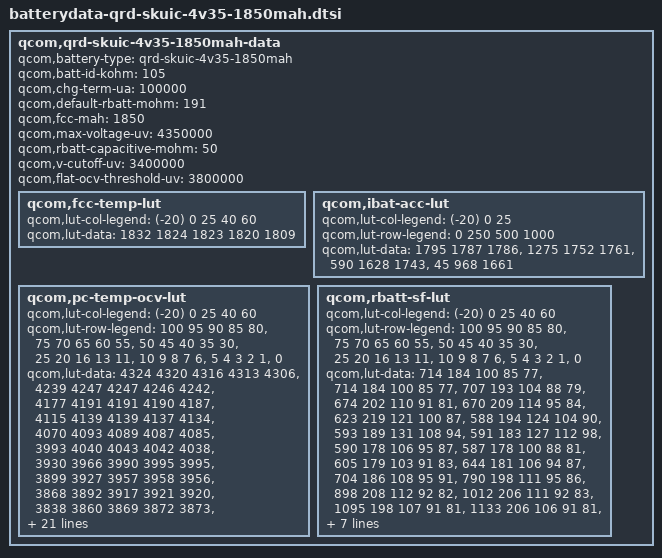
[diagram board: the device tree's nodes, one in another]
/* Copyright (c) 2014, The Linux Foundation. All rights reserved.
 *
 * This program is free software; you can redistribute it and/or modify
 * it under the terms of the GNU General Public License version 2 and
 * only version 2 as published by the Free Software Foundation.
 *
 * This program is distributed in the hope that it will be useful,
 * but WITHOUT ANY WARRANTY; without even the implied warranty of
 * MERCHANTABILITY or FITNESS FOR A PARTICULAR PURPOSE.  See the
 * GNU General Public License for more details.
 */

qcom,qrd-skuic-4v35-1850mah-data {
	qcom,battery-type = "qrd-skuic-4v35-1850mah";
	qcom,batt-id-kohm = <105>;
	qcom,chg-term-ua = <100000>;
	qcom,default-rbatt-mohm = <191>;
	qcom,fcc-mah = <1850>;
	qcom,max-voltage-uv = <4350000>;
	qcom,rbatt-capacitive-mohm = <50>;
	qcom,v-cutoff-uv = <3400000>;
	qcom,flat-ocv-threshold-uv = <3800000>;

	qcom,fcc-temp-lut {
		qcom,lut-col-legend = <(-20) 0 25 40 60>;
		qcom,lut-data = <1832 1824 1823 1820 1809>;
	};

	qcom,ibat-acc-lut {
		qcom,lut-col-legend = <(-20) 0 25>;
		qcom,lut-row-legend = <0 250 500 1000>;
		qcom,lut-data = <1795 1787 1786>,
				<1275 1752 1761>,
				<590 1628 1743>,
				<45 968 1661>;
	};

	qcom,pc-temp-ocv-lut {
		qcom,lut-col-legend = <(-20) 0 25 40 60>;
		qcom,lut-row-legend = <100 95 90 85 80>,
					<75 70 65 60 55>,
					<50 45 40 35 30>,
					<25 20 16 13 11>,
					<10 9 8 7 6>,
					<5 4 3 2 1>,
					<0>;
		qcom,lut-data = <4324 4320 4316 4313 4306>,
				<4239 4247 4247 4246 4242>,
				<4177 4191 4191 4190 4187>,
				<4115 4139 4139 4137 4134>,
				<4070 4093 4089 4087 4085>,
				<3993 4040 4043 4042 4038>,
				<3930 3966 3990 3995 3995>,
				<3899 3927 3957 3958 3956>,
				<3868 3892 3917 3921 3920>,
				<3838 3860 3869 3872 3873>,
				<3808 3834 3837 3838 3839>,
				<3787 3812 3814 3815 3815>,
				<3771 3793 3796 3797 3796>,
				<3759 3781 3781 3780 3781>,
				<3748 3774 3772 3767 3760>,
				<3738 3764 3760 3752 3739>,
				<3726 3742 3739 3730 3716>,
				<3715 3717 3709 3700 3688>,
				<3702 3704 3692 3683 3670>,
				<3691 3699 3687 3678 3667>,
				<3685 3697 3686 3677 3666>,
				<3675 3695 3684 3676 3665>,
				<3664 3692 3683 3675 3663>,
				<3645 3686 3679 3670 3658>,
				<3619 3670 3664 3653 3638>,
				<3584 3637 3631 3618 3601>,
				<3535 3586 3580 3567 3551>,
				<3467 3520 3514 3500 3486>,
				<3368 3429 3424 3409 3398>,
				<3231 3299 3287 3265 3263>,
				<3005 3000 3000 3000 3000>;
	};

	qcom,rbatt-sf-lut {
		qcom,lut-col-legend = <(-20) 0 25 40 60>;
		qcom,lut-row-legend = <100 95 90 85 80>,
					<75 70 65 60 55>,
					<50 45 40 35 30>,
					<25 20 16 13 11>,
					<10 9 8 7 6>,
					<5 4 3 2 1>,
					<0>;
		qcom,lut-data = <714 184 100 85 77>,
				<714 184 100 85 77>,
				<707 193 104 88 79>,
				<674 202 110 91 81>,
				<670 209 114 95 84>,
				<623 219 121 100 87>,
				<588 194 124 104 90>,
				<593 189 131 108 94>,
				<591 183 127 112 98>,
				<590 178 106 95 87>,
				<587 178 100 88 81>,
				<605 179 103 91 83>,
				<644 181 106 94 87>,
				<704 186 108 95 91>,
				<790 198 111 95 86>,
				<898 208 112 92 82>,
				<1012 206 111 92 83>,
				<1095 198 107 91 81>,
				<1133 206 106 91 81>,
				<1100 218 110 94 85>,
				<1036 225 114 97 86>,
				<789 216 114 98 88>,
				<823 214 116 99 88>,
				<865 221 118 100 88>,
				<922 223 116 97 85>,
				<991 222 111 94 84>,
				<1069 229 111 95 86>,
				<1212 249 116 99 90>,
				<1665 284 128 108 96>,
				<4956 452 178 153 109>,
				<52816 21422 16264 30119 400>;
	};
};
